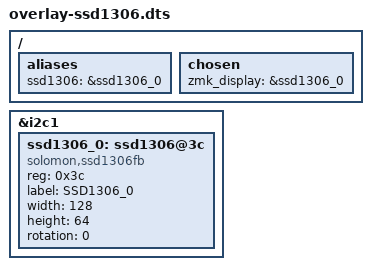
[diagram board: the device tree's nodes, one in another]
/dts-v1/;

/*
 * overlay-ssd1306.dts
 *
 * Minimal safe 3.3V SSD1306 128x64 overlay for the Corne shield.
 *
 * Notes:
 *  - Uses I2C controller &i2c1 by default. Change to &i2c0 / &i2c2 if your
 *    board uses a different controller.
 *  - Uses I2C address 0x3C (common). Change `reg` to 0x3D if required.
 *  - This overlay assumes the OLED is powered from the board 3.3V rail.
 *    Do NOT power the OLED from 5V unless the module explicitly supports it.
 *
 * Implementation details:
 *  - Define the SSD1306 node first (under the referenced I2C controller) and
 *    then provide a single root block containing `aliases` and `chosen` that
 *    reference that node. This ordering avoids devicetree forward-reference
 *    issues during gen_defines.py processing.
 */

/* Enable the I2C controller used by the OLED and add the SSD1306 node. */
&i2c1 {
	status = "okay";

	/* Node name `ssd1306_0` used by aliases / chosen below. */
	ssd1306_0: ssd1306@3c {
		compatible = "solomon,ssd1306fb";
		reg = <0x3c>; /* I2C address */

		label = "SSD1306_0";
		width = <128>;
		height = <64>;

		/* rotation optional (0, 90, 180, 270) depending on physical mount */
		rotation = <0>;

		/* Keep node enabled */
		status = "okay";

		/* Optional: if your module exposes a reset / dc pin or regulator,
		 * add reset-gpios / vcc-supply entries here with the correct phandles.
		 */
	};
};

/ {
	/* Make the node discoverable via DT_ALIAS(ssd1306) */
	aliases {
		ssd1306 = &ssd1306_0;
	};

	/* Some firmware setups look for a chosen display node named zmk_display */
	chosen {
		zmk_display = &ssd1306_0;
	};
};
